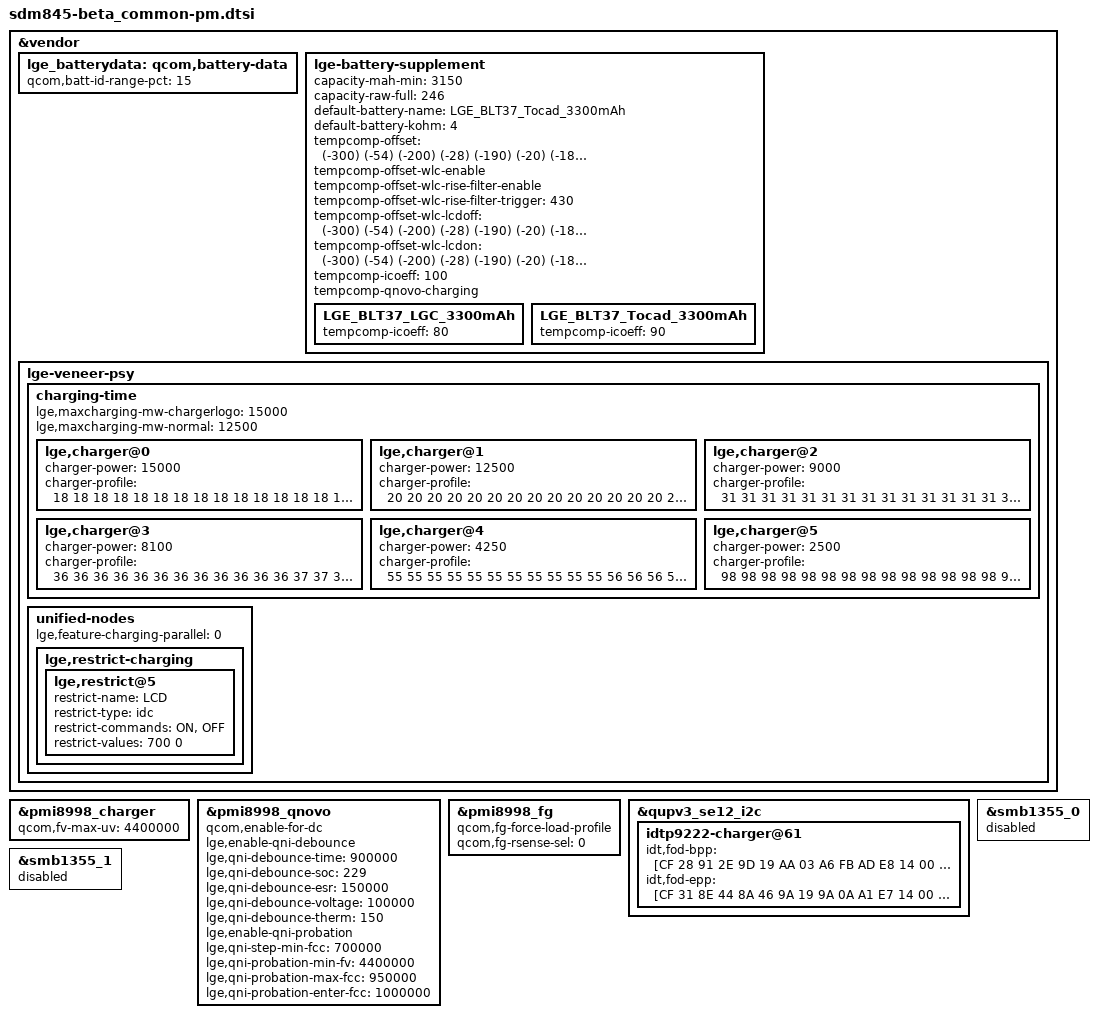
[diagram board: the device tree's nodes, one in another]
/* Copyright (c) 2017, The Linux Foundation. All rights reserved.
 *
 * This program is free software; you can redistribute it and/or modify
 * it under the terms of the GNU General Public License version 2 and
 * only version 2 as published by the Free Software Foundation.
 *
 * This program is distributed in the hope that it will be useful,
 * but WITHOUT ANY WARRANTY; without even the implied warranty of
 * MERCHANTABILITY or FITNESS FOR A PARTICULAR PURPOSE.  See the
 * GNU General Public License for more details.
 */

#include "../sdm845-judy_common/sdm845-judy_common-pm.dtsi"

&vendor {
	lge_batterydata: qcom,battery-data {
		qcom,batt-id-range-pct = <15>;
		#include "../../sdm845-battery/LGE_BLT37_LGC_3300mAh.dtsi"
		#include "../../sdm845-battery/LGE_BLT37_Tocad_3300mAh.dtsi"
	};

	lge-battery-supplement {
		capacity-mah-min = <3150>;
		capacity-raw-full = <246>;

		default-battery-name = "LGE_BLT37_Tocad_3300mAh";
		default-battery-kohm = <4>;

		/* format : (temp index) (temp delta) */
		tempcomp-offset = <
			(-300) (-54)
			(-200) (-28)
			(-190) (-20)
			(-180) (-12)
			(-170) ( -8)
			(-160) ( -4)
			(-150)    0
			(-100)    8
			(-50)     9
			0         8
			50        6
			100       1
			150    ( -4)
			200    ( -9)
			250    (-12)
			300    (-21)
			350    (-26)
			400    (-31)
			450    (-34)
			500    (-32)
			550    (-30)
			600    (-24)
			700    (-11)
			800    (-11)
			900    (-11)
		>;

		tempcomp-offset-wlc-enable;
		tempcomp-offset-wlc-rise-filter-enable;
		tempcomp-offset-wlc-rise-filter-trigger = <430>;
		tempcomp-offset-wlc-lcdoff = <
			(-300) (-54)
			(-200) (-28)
			(-190) (-20)
			(-180) (-12)
			(-170) ( -8)
			(-160) ( -4)
			(-150)    0
			(-100)    8
			(-50)     9
			0         8
			50        6
			100       1
			150    ( -4)
			200    ( -9)
			250    (-12)
			300    (-21)
			350    (-26)
			400    (-31)
			450    (-34)
			500    (-32)
			550    (-30)
			600    (-24)
			700    (-11)
			800    (-11)
			900    (-11)
		>;

		tempcomp-offset-wlc-lcdon = <
			(-300) (-54)
			(-200) (-28)
			(-190) (-20)
			(-180) (-12)
			(-170) ( -8)
			(-160) ( -4)
			(-150)    0
			(-100)    8
			(-50)     9
			0         8
			50        6
			100       1
			150    ( -4)
			200    ( -9)
			250    (-12)
			300    (-21)
			350    (-30)
			400    (-40)
			450    (-50)
			500    (-70)
			550    (-30)
			600    (-24)
			700    (-11)
			800    (-11)
			900    (-11)
		>;
		tempcomp-icoeff = <100>;
		tempcomp-qnovo-charging;

		/* overriding by battery type */
		LGE_BLT37_LGC_3300mAh {
			tempcomp-icoeff = <80>;
		};
		LGE_BLT37_Tocad_3300mAh {
			tempcomp-icoeff = <90>;
		};
	};

	lge-veneer-psy {
		charging-time {
			#address-cells = <1>;
			#size-cells = <0>;

			lge,maxcharging-mw-chargerlogo = <15000>;
			lge,maxcharging-mw-normal = <12500>;

			lge,charger@0 {		//  fast charger: 9000mV * 1660mA or 5000mV * 3000mA
				charger-power = <15000>;
				charger-profile = <
					18  18  18  18  18  18  18  18  18  18  18  18  18  18  18  18
					18  18  18  18  18  18  18  18  18  18  18  18  18  18  18  18
					18  18  18  18  18  18  18  18  18  18  18  18  18  18  18  18
					18  18  18  18  18  18  18  18  18  18  18  18  18  18  18  18
					18  18  18  18  18  18  18  18  18  18  18  18  18  18  18  18
					18  18  18  18  18  18  18  18  18  18  18  18  18  18  18  18
					18  18  18  18  18  18  18  18  18  18  18  18  18  18  18  18
					18  18  18  18  18  18  18  18  18  18  18  18  18  18  18  18
					18  18  18  18  18  18  18  18  18  18  18  18  18  18  18  18
					18  18  18  18  18  18  18  18  18  18  18  21  21  21  21  21
					21  21  21  21  21  21  21  21  25  25  25  25  25  25  25  25
					25  25  25  25  25  25  25  25  25  25  25  25  25  29  29  29
					29  29  29  29  29  29  29  29  29  29  29  29  33  33  33  33
					33  33  33  33  33  35  35  45  45  45  45  45  45  45  45  45
					45  54  54  54  54  54  54  54  58  52  53  54  55  59  62  68
					74  80  85  93  99 108 108 108 108 108 108 108 108 108 108 108
				>;
			};
			lge,charger@1 {		//  power-on fast charger: 2.5A * 4.0V / 80% = 12.5W
				charger-power = <12500>;
				charger-profile = <
					20  20  20  20  20  20  20  20  20  20  20  20  20  20  20  20
					20  20  20  20  20  20  20  20  20  20  20  20  20  20  20  20
					20  20  20  20  20  20  20  20  20  20  20  20  20  20  20  20
					20  20  20  20  20  20  20  20  20  20  20  20  20  20  20  20
					20  20  20  20  20  20  20  20  20  20  20  20  20  20  20  20
					20  20  20  20  20  20  20  20  20  20  20  20  20  20  20  20
					20  20  20  20  20  20  20  20  20  20  20  20  20  20  20  20
					20  20  20  20  20  20  20  20  20  20  20  20  20  20  20  20
					20  20  20  20  20  20  20  20  20  20  20  20  20  20  20  20
					20  20  20  20  20  20  20  20  20  20  20  20  20  20  20  20
					20  20  20  20  20  20  20  20  24  24  24  24  24  24  24  24
					24  24  24  24  24  24  24  24  24  24  24  24  24  28  28  28
					28  28  28  28  28  28  28  28  28  28  28  28  31  31  31  31
					31  31  31  31  31  34  34  43  43  43  43  43  43  43  43  43
					43  52  52  52  52  52  52  52  55  52  53  54  55  59  62  68
					74  80  85  93  99 108 108 108 108 108 108 108 108 108 108 108
				>;
			};
			lge,charger@2 {		//  dcp charger: 5000mV * 1800mA = 9W
				charger-power = <9000>;
				charger-profile = <
					31  31  31  31  31  31  31  31  31  31  31  31  31  31  31  31
					31  31  31  31  31  31  31  31  31  31  31  31  31  31  31  31
					31  31  31  31  31  31  31  31  31  31  31  31  31  31  31  31
					31  31  31  31  31  31  31  31  31  31  31  31  31  31  31  31
					31  31  31  31  31  31  31  31  31  31  31  31  31  31  31  31
					31  31  31  31  31  31  31  31  31  31  31  31  31  31  31  31
					31  31  31  31  31  31  31  31  31  31  31  31  31  31  31  31
					31  31  31  31  31  31  31  31  31  31  31  31  31  31  31  31
					31  31  31  31  31  31  31  31  31  31  31  31  31  31  31  31
					31  31  31  31  31  31  31  31  31  31  31  31  31  31  31  31
					31  31  31  31  31  31  31  31  31  31  31  31  31  31  31  31
					31  31  31  31  31  31  31  31  31  31  31  31  31  31  31  31
					31  31  31  31  31  31  31  31  31  31  31  31  31  31  31  31
					31  31  31  31  34  34  34  34  34  34  34  34  34  34  42  42
					42  42  42  42  55  55  55  55  55  55  69  69  69  69  69  69
					70  75  80  90 100 105 105 105 105 105 105 105 105 105 105 105
				>;
			};
			lge,charger@3 {		// EPP wireless charger: 9000mV * 900mA = 8.1W
				charger-power = <8100>;
				charger-profile = <
					36  36  36  36  36  36  36  36  36  36  36  36  37  37  37  37
					37  37  37  37  37  37  37  37  37  37  38  38  38  38  38  38
					38  38  38  38  38  38  38  38  39  39  39  39  39  39  39  39
					39  39  39  39  40  40  40  40  40  40  40  40  40  40  40  40
					41  41  41  41  41  41  41  41  41  41  41  41  42  42  42  42
					42  42  42  42  42  42  42  43  43  43  43  43  43  43  43  43
					43  44  44  44  44  44  44  44  44  44  44  45  45  45  45  45
					45  45  45  45  46  46  46  46  46  46  46  46  46  47  47  47
					47  47  47  47  47  47  48  48  48  48  48  48  48  48  49  49
					49  49  49  49  49  49  50  50  50  50  50  50  50  50  51  51
					51  51  51  51  51  52  52  52  52  52  52  52  53  53  53  53
					53  53  53  54  54  54  54  54  54  54  55  55  55  55  55  55
					56  56  56  56  56  56  57  57  57  57  57  57  58  58  58  58
					58  58  59  59  59  59  59  60  60  60  60  60  61  61  61  61
					61  61  62  62  62  62  60  60  60  60  60  60  60  60  60  60
					70  75  80  90 100 105 105 105 105 105 105 105 105 105 105 105
				>;
			};
			lge,charger@4 {		// BPP wireless charger: 5000mV * 850mA = 4.25W
				charger-power = <4250>;
				charger-profile = <
					55  55  55  55  55  55  55  55  55  55  55  56  56  56  56  56
					56  56  56  56  56  56  56  56  56  56  56  56  56  56  56  56
					56  56  56  56  56  56  56  56  56  57  57  57  57  57  57  57
					57  57  57  57  57  57  57  57  57  57  57  57  57  57  57  57
					57  57  57  57  57  57  57  58  58  58  58  58  58  58  58  58
					58  58  58  58  58  58  58  58  58  58  58  58  58  58  58  58
					58  58  58  59  59  59  59  59  59  59  59  59  59  59  59  59
					59  59  59  59  59  59  59  59  59  59  59  59  59  59  59  60
					60  60  60  60  60  60  60  60  60  60  60  60  60  60  60  60
					60  60  60  60  60  60  60  60  60  61  61  61  61  61  61  61
					61  61  61  61  61  61  61  61  61  61  61  61  61  61  61  61
					61  61  61  62  62  62  62  62  62  62  62  62  62  62  62  62
					62  62  62  62  62  62  62  62  62  62  62  63  63  63  63  63
					63  63  63  63  63  63  63  63  63  63  63  63  60  60  60  60
					60  60  60  60  60  60  60  60  60  60  60  65  65  65  65  65
					70  75  80  90 100 105 105 105 105 105 105 105 105 105 105 105
				>;
			};
			lge,charger@5 {		// SDP: 5000mV * 500mA = 2.5W
				charger-power = <2500>;
				charger-profile = <
					98  98  98  98  98  98  98  98  98  98  98  98  98  98  98  98
					98  98  98  98  98  98  98  98  98  98  98  98  98  98  98  98
					98  98  98  98  98  98  98  98  98  98  98  98  98  98  98  98
					98  98  98  98  98  98  98  98  98  98  98  98  98  98  98  98
					98  98  98  98  98  98  98  98  98  98  98  98  98  98  98  98
					98  98  98  98  98  98  98  98  98  98  98  98  98  98  98  98
					98  98  98  98  98  98  98  98  98  98  98  98  98  98  98  98
					98  98  98  98  98  98  98  98  98  98  98  98  98  98  98  98
					98  98  98  98  98  98  98  98  98  98  98  98  98  98  98  98
					98  98  98  98  98  98  98  98  98  98  98  98  98  98  98  98
					98  98  98  98  98  98  98  98  98  98  98  98  98  98  98  98
					98  98  98  98  98  98  98  98  98  98  98  98  98  98  98  98
					98  98  98  98  98  98  98  98  98  98  98  98  98  98  98  98
					98  98  98  98  98  98  98  98  98  98  98  98  98  98  98  98
					98  98  98  98  98  98  98  98  98  98  98  98  98  98  98  98
					98  98  98  98  98 110 110 110 110 110 110 110 110 110 110 110
				>;
			};
		};

		unified-nodes {
			lge,feature-charging-parallel = <0>;

			lge,restrict-charging {
				lge,restrict@5 {
					restrict-name = "LCD";
					restrict-type = "idc";
					restrict-commands = "ON", "OFF";
					restrict-values = < 700      0>;
				};
			};
		};
	};
};

&pmi8998_charger {
	qcom,fv-max-uv = <4400000>;
};

&pmi8998_qnovo {
	qcom,enable-for-dc;

	lge,enable-qni-debounce;
	lge,qni-debounce-time = <900000>;
	lge,qni-debounce-soc = <229>;
	lge,qni-debounce-esr = <150000>;
	lge,qni-debounce-voltage = <100000>;
	lge,qni-debounce-therm = <150>;

	lge,enable-qni-probation;
	lge,qni-step-min-fcc = <700000>;
	lge,qni-probation-min-fv = <4400000>;
	lge,qni-probation-max-fcc = <950000>;
	lge,qni-probation-enter-fcc = <1000000>;
};

&pmi8998_fg {
	qcom,fg-force-load-profile;
	qcom,fg-rsense-sel = <0>;
};

&qupv3_se12_i2c {
	idtp9222-charger@61 {
		// FOD parameters
		idt,fod-bpp = [CF 28 91 2E 9D 19 AA 03 A6 FB AD E8 14 00 00 00];
		idt,fod-epp = [CF 31 8E 44 8A 46 9A 19 9A 0A A1 E7 14 00 64 32];
	};
};

&smb1355_0 {
	status = "disabled";
};

&smb1355_1 {
	status = "disabled";
};
